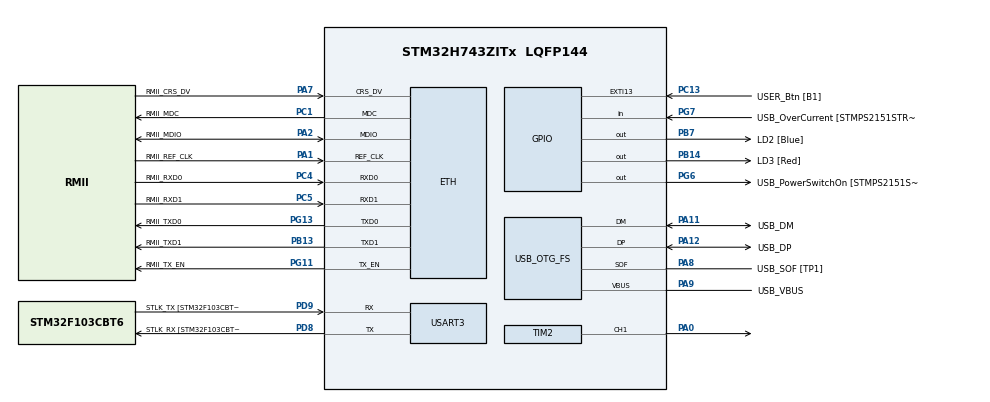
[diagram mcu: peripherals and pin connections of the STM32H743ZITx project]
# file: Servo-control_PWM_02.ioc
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ETH.MediaInterface=HAL_ETH_RMII_MODE
Mcu.Family=STM32H7
Mcu.Name=STM32H743ZITx
Mcu.Package=LQFP144
NVIC.PriorityGroup=NVIC_PRIORITYGROUP_4
NVIC.TIM2_IRQn=true\:0\:0\:false\:false\:true\:true\:true
PA0.Signal=S_TIM2_CH1
PA1.GPIO_Label=RMII_REF_CLK
PA1.Mode=RMII
PA1.Signal=ETH_REF_CLK
PA10.GPIO_Label=USB_ID
PA10.Signal=USB_OTG_FS_ID
PA11.GPIO_Label=USB_DM
PA11.Mode=Device_Only
PA11.Signal=USB_OTG_FS_DM
PA12.GPIO_Label=USB_DP
PA12.Mode=Device_Only
PA12.Signal=USB_OTG_FS_DP
PA2.GPIO_Label=RMII_MDIO
PA2.Mode=RMII
PA2.Signal=ETH_MDIO
PA7.GPIO_Label=RMII_CRS_DV
PA7.Mode=RMII
PA7.Signal=ETH_CRS_DV
PA8.GPIO_Label=USB_SOF [TP1]
PA8.Mode=Activate_SOF_FS
PA8.Signal=USB_OTG_FS_SOF
PA9.GPIO_Label=USB_VBUS
PA9.Mode=Activate_VBUS
PA9.Signal=USB_OTG_FS_VBUS
PB13.GPIO_Label=RMII_TXD1
PB13.Mode=RMII
PB13.Signal=ETH_TXD1
PB14.GPIO_Label=LD3 [Red]
PB14.Signal=GPIO_Output
PB7.GPIO_Label=LD2 [Blue]
PB7.Signal=GPIO_Output
PC1.GPIO_Label=RMII_MDC
PC1.Mode=RMII
PC1.Signal=ETH_MDC
PC13.GPIO_Label=USER_Btn [B1]
PC13.Signal=GPXTI13
PC14-OSC32_IN\ (OSC32_IN).Mode=LSE-External-Oscillator
PC14-OSC32_IN\ (OSC32_IN).Signal=RCC_OSC32_IN
PC15-OSC32_OUT\ (OSC32_OUT).Mode=LSE-External-Oscillator
PC15-OSC32_OUT\ (OSC32_OUT).Signal=RCC_OSC32_OUT
PC4.GPIO_Label=RMII_RXD0
PC4.Mode=RMII
PC4.Signal=ETH_RXD0
PC5.GPIO_Label=RMII_RXD1
PC5.Mode=RMII
PC5.Signal=ETH_RXD1
PD8.GPIO_Label=STLK_RX [STM32F103CBT6_PA3]
PD8.Mode=Asynchronous
PD8.Signal=USART3_TX
PD9.GPIO_Label=STLK_TX [STM32F103CBT6_PA2]
PD9.Mode=Asynchronous
PD9.Signal=USART3_RX
PG11.GPIO_Label=RMII_TX_EN
PG11.Mode=RMII
PG11.Signal=ETH_TX_EN
PG13.GPIO_Label=RMII_TXD0
PG13.Mode=RMII
PG13.Signal=ETH_TXD0
PG6.GPIO_Label=USB_PowerSwitchOn [STMPS2151STR_EN]
PG6.Signal=GPIO_Output
PG7.GPIO_Label=USB_OverCurrent [STMPS2151STR_FAULT]
PG7.Signal=GPIO_Input
PH0-OSC_IN\ (PH0).GPIO_Label=MCO
PH0-OSC_IN\ (PH0).Mode=HSE-External-Oscillator
PH0-OSC_IN\ (PH0).Signal=RCC_OSC_IN
PH1-OSC_OUT\ (PH1).Mode=HSE-External-Oscillator
PH1-OSC_OUT\ (PH1).Signal=RCC_OSC_OUT
ProjectManager.HeapSize=0x200
ProjectManager.StackSize=0x400
ProjectManager.TargetToolchain=STM32CubeIDE
RCC.48MHZClocksFreq_Value=24000000
RCC.ADCFreq_Value=16125000
RCC.AHBFreq_Value=216000000
RCC.APB1CLKDivider=RCC_HCLK_DIV4
RCC.APB1Freq_Value=90000000
RCC.APB1TimFreq_Value=108000000
RCC.APB2CLKDivider=RCC_HCLK_DIV2
RCC.APB2Freq_Value=90000000
RCC.APB2TimFreq_Value=216000000
RCC.APB3Freq_Value=90000000
RCC.APB4Freq_Value=90000000
RCC.CortexFreq_Value=180000000
RCC.D1CPRE=RCC_SYSCLK_DIV2
RCC.D1PPRE=RCC_APB3_DIV2
RCC.D2PPRE1=RCC_APB1_DIV2
RCC.D2PPRE2=RCC_APB2_DIV2
RCC.D3PPRE=RCC_APB4_DIV2
RCC.DIVM1=1
RCC.DIVN1=90
RCC.DIVQ1=15
RCC.HCLKFreq_Value=180000000
RCC.HSE_VALUE=8000000
RCC.HSI_VALUE=64000000
RCC.PLL2FRACN=0
RCC.PLL3FRACN=0
RCC.PLLFRACN=0
RCC.PLLM=25
RCC.PLLMUL=RCC_PLL_MUL9
RCC.PLLN=432
RCC.PLLQ=9
RCC.PRESCALERUSB=RCC_USBCLKSOURCE_PLL_DIV1_5
RCC.PWR_Regulator_Voltage_Scale=PWR_REGULATOR_VOLTAGE_SCALE1
RCC.SYSCLKFreq_VALUE=360000000
RCC.SYSCLKSource=RCC_SYSCLKSOURCE_PLLCLK
RCC.SYSCLKSourceVirtual=RCC_SYSCLKSOURCE_PLLCLK
RCC.USBFreq_Value=48000000
RCC.VCOOutputFreq_Value=432000000
SH.S_TIM2_CH1.0=TIM2_CH1,PWM Generation1 CH1
TIM2.AutoReloadPreload=TIM_AUTORELOAD_PRELOAD_DISABLE
TIM2.Channel-PWM\ Generation1\ CH1=TIM_CHANNEL_1
TIM2.Period=36000-1
TIM2.Prescaler=9
TIM2.TIM2_ETR_REMAP-ETR_as_clearing_source_through_remap_TIM2=TIM_TIM2_ETR_COMP1_OUT
USART3.VirtualMode-Asynchronous=VM_ASYNC
USB_OTG_FS.VirtualMode=Device_Only
VP_TIM2_VS_ClockSourceINT.Mode=Internal
VP_TIM2_VS_NoETR.Mode=ETR_as_clearing_source_through_remap_TIM2
board=NUCLEO-H743ZI

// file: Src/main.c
/* USER CODE BEGIN Header */
/**
  ******************************************************************************
  * @file           : main.c
  * @brief          : Main program body
  ******************************************************************************
  * @attention
  *
  * <h2><center>&copy; Copyright (c) 2019 STMicroelectronics.
  * All rights reserved.</center></h2>
  *
  * This software component is licensed by ST under BSD 3-Clause license,
  * the "License"; You may not use this file except in compliance with the
  * License. You may obtain a copy of the License at:
  *                        opensource.org/licenses/BSD-3-Clause
  *
  ******************************************************************************
  */
/* USER CODE END Header */

#include "main.h"
#include "eth.h"
#include "tim.h"
#include "usart.h"
#include "usb_otg.h"
#include "gpio.h"

void SystemClock_Config(void);

int main(void)
{

  /* MCU Configuration--------------------------------------------------------*/

  /* Reset of all peripherals, Initializes the Flash interface and the Systick. */
  HAL_Init();

  /* Configure the system clock */
  SystemClock_Config();

  /* Initialize all configured peripherals */
  MX_GPIO_Init();
  MX_ETH_Init();
  MX_USART3_UART_Init();
  MX_USB_OTG_FS_PCD_Init();
  MX_TIM2_Init();
  /* USER CODE BEGIN 2 */
  HAL_TIM_PWM_Start(&htim2, TIM_CHANNEL_1); //Start the PWM.
  /* USER CODE END 2 */

  /* Infinite loop */
  /* USER CODE BEGIN WHILE */
  while (1)
  {
	  int i=180;
    /* USER CODE END WHILE */
	 for(i=180;i<270;i++)
	 {
		 htim2.Instance->CCR1 = i; //0 degree at Duty cycle 1ms.
		 HAL_Delay(200);
	 }
	 /* htim2.Instance->CCR1 = 180; //0 degree at Duty cycle 1ms.
	  	  HAL_Delay(2000);

	  	  htim2.Instance->CCR1 = 270; //90 degree at Duty cycle 1.5ms.
	  	  HAL_Delay(2000);

	  	  htim2.Instance->CCR1 = 3000; //180 degree at Duty cycle 2ms.
	  	  HAL_Delay(2000);

	  	  HAL_Delay(2000);*/
  }
}

void SystemClock_Config(void)
{
  RCC_OscInitTypeDef RCC_OscInitStruct = {0};
  RCC_ClkInitTypeDef RCC_ClkInitStruct = {0};
  RCC_PeriphCLKInitTypeDef PeriphClkInitStruct = {0};

  /** Supply configuration update enable
  */
  HAL_PWREx_ConfigSupply(PWR_LDO_SUPPLY);
  /** Configure the main internal regulator output voltage
  */
  __HAL_PWR_VOLTAGESCALING_CONFIG(PWR_REGULATOR_VOLTAGE_SCALE1);

  while(!__HAL_PWR_GET_FLAG(PWR_FLAG_VOSRDY)) {}
  /** Initializes the CPU, AHB and APB busses clocks
  */
  RCC_OscInitStruct.OscillatorType = RCC_OSCILLATORTYPE_HSE;
  RCC_OscInitStruct.HSEState = RCC_HSE_ON;
  RCC_OscInitStruct.PLL.PLLState = RCC_PLL_ON;
  RCC_OscInitStruct.PLL.PLLSource = RCC_PLLSOURCE_HSE;
  RCC_OscInitStruct.PLL.PLLM = 1;
  RCC_OscInitStruct.PLL.PLLN = 90;
  RCC_OscInitStruct.PLL.PLLP = 2;
  RCC_OscInitStruct.PLL.PLLQ = 15;
  RCC_OscInitStruct.PLL.PLLR = 2;
  RCC_OscInitStruct.PLL.PLLRGE = RCC_PLL1VCIRANGE_3;
  RCC_OscInitStruct.PLL.PLLVCOSEL = RCC_PLL1VCOWIDE;
  RCC_OscInitStruct.PLL.PLLFRACN = 0;
  if (HAL_RCC_OscConfig(&RCC_OscInitStruct) != HAL_OK)
  {
    Error_Handler();
  }
  /** Initializes the CPU, AHB and APB busses clocks
  */
  RCC_ClkInitStruct.ClockType = RCC_CLOCKTYPE_HCLK|RCC_CLOCKTYPE_SYSCLK
                              |RCC_CLOCKTYPE_PCLK1|RCC_CLOCKTYPE_PCLK2
                              |RCC_CLOCKTYPE_D3PCLK1|RCC_CLOCKTYPE_D1PCLK1;
  RCC_ClkInitStruct.SYSCLKSource = RCC_SYSCLKSOURCE_PLLCLK;
  RCC_ClkInitStruct.SYSCLKDivider = RCC_SYSCLK_DIV2;
  RCC_ClkInitStruct.AHBCLKDivider = RCC_HCLK_DIV1;
  RCC_ClkInitStruct.APB3CLKDivider = RCC_APB3_DIV2;
  RCC_ClkInitStruct.APB1CLKDivider = RCC_APB1_DIV2;
  RCC_ClkInitStruct.APB2CLKDivider = RCC_APB2_DIV2;
  RCC_ClkInitStruct.APB4CLKDivider = RCC_APB4_DIV2;

  if (HAL_RCC_ClockConfig(&RCC_ClkInitStruct, FLASH_LATENCY_2) != HAL_OK)
  {
    Error_Handler();
  }
  PeriphClkInitStruct.PeriphClockSelection = RCC_PERIPHCLK_USART3|RCC_PERIPHCLK_USB;
  PeriphClkInitStruct.Usart234578ClockSelection = RCC_USART234578CLKSOURCE_D2PCLK1;
  PeriphClkInitStruct.UsbClockSelection = RCC_USBCLKSOURCE_PLL;
  if (HAL_RCCEx_PeriphCLKConfig(&PeriphClkInitStruct) != HAL_OK)
  {
    Error_Handler();
  }
  /** Enable USB Voltage detector
  */
  HAL_PWREx_EnableUSBVoltageDetector();
}

void Error_Handler(void)
{
}

/************************ (C) COPYRIGHT STMicroelectronics *****END OF FILE****/
